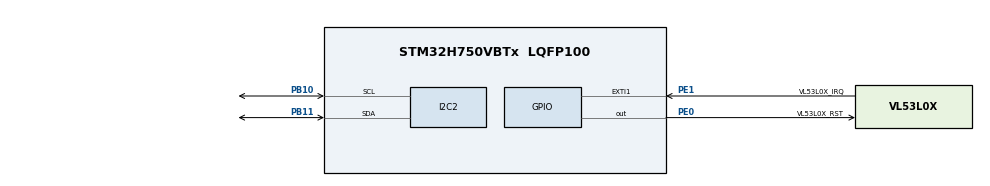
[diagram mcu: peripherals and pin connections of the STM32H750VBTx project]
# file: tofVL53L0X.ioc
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Mcu.Family=STM32H7
Mcu.Name=STM32H750VBTx
Mcu.Package=LQFP100
NVIC.EXTI1_IRQn=true\:0\:0\:false\:false\:true\:true\:true
NVIC.PriorityGroup=NVIC_PRIORITYGROUP_4
PB10.Mode=I2C
PB10.Signal=I2C2_SCL
PB11.Mode=I2C
PB11.Signal=I2C2_SDA
PE0.GPIO_Label=VL53L0X_RST
PE0.Signal=GPIO_Output
PE1.GPIO_Label=VL53L0X_IRQ
PE1.GPIO_ModeDefaultEXTI=GPIO_MODE_IT_FALLING
PE1.GPIO_PuPd=GPIO_PULLUP
PE1.Signal=GPXTI1
ProjectManager.HeapSize=0x200
ProjectManager.StackSize=0x400
ProjectManager.TargetToolchain=STM32CubeIDE
RCC.ADCFreq_Value=129000000
RCC.APB1Freq_Value=64000000
RCC.APB2Freq_Value=64000000
RCC.APB3Freq_Value=64000000
RCC.APB4Freq_Value=64000000
RCC.CortexFreq_Value=64000000
RCC.HCLKFreq_Value=64000000
RCC.SYSCLKFreq_VALUE=64000000
RCC.USBFreq_Value=129000000
board=custom

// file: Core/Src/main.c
/* USER CODE BEGIN Header */
/**
  ******************************************************************************
  * @file           : main.c
  * @brief          : Main program body
  ******************************************************************************
  * @attention
  *
  * <h2><center>&copy; Copyright (c) 2021 STMicroelectronics.
  * All rights reserved.</center></h2>
  *
  * This software component is licensed by ST under BSD 3-Clause license,
  * the "License"; You may not use this file except in compliance with the
  * License. You may obtain a copy of the License at:
  *                        opensource.org/licenses/BSD-3-Clause
  *
  ******************************************************************************
  */
/* USER CODE END Header */
#include "main.h"

I2C_HandleTypeDef hi2c2;

void SystemClock_Config(void);
static void MX_GPIO_Init(void);
static void MX_I2C2_Init(void);

/* USER CODE BEGIN 0 */
uint32_t	status,tof_rev_id;
/* USER CODE END 0 */

int main(void)
{

  /* MCU Configuration--------------------------------------------------------*/

  /* Reset of all peripherals, Initializes the Flash interface and the Systick. */
  HAL_Init();

  /* Configure the system clock */
  SystemClock_Config();

  /* Initialize all configured peripherals */
  MX_GPIO_Init();
  MX_I2C2_Init();
  /* USER CODE BEGIN 2 */
  HAL_GPIO_WritePin(VL53L0X_RST_GPIO_Port, VL53L0X_RST_Pin, GPIO_PIN_RESET);
  HAL_Delay(2);
  HAL_GPIO_WritePin(VL53L0X_RST_GPIO_Port, VL53L0X_RST_Pin, GPIO_PIN_SET);
  HAL_Delay(2);
  SintMate_VL53L0X_Init();
  /* USER CODE END 2 */

  /* Infinite loop */
  /* USER CODE BEGIN WHILE */
  while (1)
  {
	  SintMate_VL53L0X_StartMeasure();

	  HAL_Delay(1000);
    /* USER CODE END WHILE */

  }
}

void SystemClock_Config(void)
{
  RCC_OscInitTypeDef RCC_OscInitStruct = {0};
  RCC_ClkInitTypeDef RCC_ClkInitStruct = {0};
  RCC_PeriphCLKInitTypeDef PeriphClkInitStruct = {0};

  /** Supply configuration update enable
  */
  HAL_PWREx_ConfigSupply(PWR_LDO_SUPPLY);
  /** Configure the main internal regulator output voltage
  */
  __HAL_PWR_VOLTAGESCALING_CONFIG(PWR_REGULATOR_VOLTAGE_SCALE3);

  while(!__HAL_PWR_GET_FLAG(PWR_FLAG_VOSRDY)) {}
  /** Initializes the RCC Oscillators according to the specified parameters
  * in the RCC_OscInitTypeDef structure.
  */
  RCC_OscInitStruct.OscillatorType = RCC_OSCILLATORTYPE_HSI;
  RCC_OscInitStruct.HSIState = RCC_HSI_DIV1;
  RCC_OscInitStruct.HSICalibrationValue = RCC_HSICALIBRATION_DEFAULT;
  RCC_OscInitStruct.PLL.PLLState = RCC_PLL_NONE;
  if (HAL_RCC_OscConfig(&RCC_OscInitStruct) != HAL_OK)
  {
    Error_Handler();
  }
  /** Initializes the CPU, AHB and APB buses clocks
  */
  RCC_ClkInitStruct.ClockType = RCC_CLOCKTYPE_HCLK|RCC_CLOCKTYPE_SYSCLK
                              |RCC_CLOCKTYPE_PCLK1|RCC_CLOCKTYPE_PCLK2
                              |RCC_CLOCKTYPE_D3PCLK1|RCC_CLOCKTYPE_D1PCLK1;
  RCC_ClkInitStruct.SYSCLKSource = RCC_SYSCLKSOURCE_HSI;
  RCC_ClkInitStruct.SYSCLKDivider = RCC_SYSCLK_DIV1;
  RCC_ClkInitStruct.AHBCLKDivider = RCC_HCLK_DIV1;
  RCC_ClkInitStruct.APB3CLKDivider = RCC_APB3_DIV1;
  RCC_ClkInitStruct.APB1CLKDivider = RCC_APB1_DIV1;
  RCC_ClkInitStruct.APB2CLKDivider = RCC_APB2_DIV1;
  RCC_ClkInitStruct.APB4CLKDivider = RCC_APB4_DIV1;

  if (HAL_RCC_ClockConfig(&RCC_ClkInitStruct, FLASH_LATENCY_0) != HAL_OK)
  {
    Error_Handler();
  }
  PeriphClkInitStruct.PeriphClockSelection = RCC_PERIPHCLK_I2C2;
  PeriphClkInitStruct.I2c123ClockSelection = RCC_I2C123CLKSOURCE_D2PCLK1;
  if (HAL_RCCEx_PeriphCLKConfig(&PeriphClkInitStruct) != HAL_OK)
  {
    Error_Handler();
  }
}

static void MX_I2C2_Init(void)
{

  hi2c2.Instance = I2C2;
  hi2c2.Init.Timing = 0x10707DBC;
  hi2c2.Init.OwnAddress1 = 0;
  hi2c2.Init.AddressingMode = I2C_ADDRESSINGMODE_7BIT;
  hi2c2.Init.DualAddressMode = I2C_DUALADDRESS_DISABLE;
  hi2c2.Init.OwnAddress2 = 0;
  hi2c2.Init.OwnAddress2Masks = I2C_OA2_NOMASK;
  hi2c2.Init.GeneralCallMode = I2C_GENERALCALL_DISABLE;
  hi2c2.Init.NoStretchMode = I2C_NOSTRETCH_DISABLE;
  if (HAL_I2C_Init(&hi2c2) != HAL_OK)
  {
    Error_Handler();
  }
  /** Configure Analogue filter
  */
  if (HAL_I2CEx_ConfigAnalogFilter(&hi2c2, I2C_ANALOGFILTER_ENABLE) != HAL_OK)
  {
    Error_Handler();
  }
  /** Configure Digital filter
  */
  if (HAL_I2CEx_ConfigDigitalFilter(&hi2c2, 0) != HAL_OK)
  {
    Error_Handler();
  }

}

static void MX_GPIO_Init(void)
{
  GPIO_InitTypeDef GPIO_InitStruct = {0};

  /* GPIO Ports Clock Enable */
  __HAL_RCC_GPIOB_CLK_ENABLE();
  __HAL_RCC_GPIOE_CLK_ENABLE();

  /*Configure GPIO pin Output Level */
  HAL_GPIO_WritePin(VL53L0X_RST_GPIO_Port, VL53L0X_RST_Pin, GPIO_PIN_RESET);

  /*Configure GPIO pin : VL53L0X_RST_Pin */
  GPIO_InitStruct.Pin = VL53L0X_RST_Pin;
  GPIO_InitStruct.Mode = GPIO_MODE_OUTPUT_PP;
  GPIO_InitStruct.Pull = GPIO_NOPULL;
  GPIO_InitStruct.Speed = GPIO_SPEED_FREQ_LOW;
  HAL_GPIO_Init(VL53L0X_RST_GPIO_Port, &GPIO_InitStruct);

  /*Configure GPIO pin : VL53L0X_IRQ_Pin */
  GPIO_InitStruct.Pin = VL53L0X_IRQ_Pin;
  GPIO_InitStruct.Mode = GPIO_MODE_IT_FALLING;
  GPIO_InitStruct.Pull = GPIO_PULLUP;
  HAL_GPIO_Init(VL53L0X_IRQ_GPIO_Port, &GPIO_InitStruct);

  /* EXTI interrupt init*/
  HAL_NVIC_SetPriority(EXTI1_IRQn, 0, 0);
  HAL_NVIC_EnableIRQ(EXTI1_IRQn);

}

void Error_Handler(void)
{
  __disable_irq();
  while (1)
  {
  }
}

/************************ (C) COPYRIGHT STMicroelectronics *****END OF FILE****/
